# dm64lc_cslr_edmatc register map
Vendor: Texas Instruments
Peripheral module from a debugger description file.
Registers are 32-bit, access not given, reset 0x0 unless marked. A register's access mark holds for its fields unless they carry their own. Offsets are as the file gives them; lines under a group give offsets from that group; [hi:lo] are bit positions; {n}, {i} and the like mark numbered series; 'fields as' and 'values as' point back to an identical list; <NAME> marks a mode.

## EDMATC — Enhanced DMA Transfer controller.
0x00 REV ro reset 0x40003B00 — Peripheral Revision
  [31:0] PID — Reserved
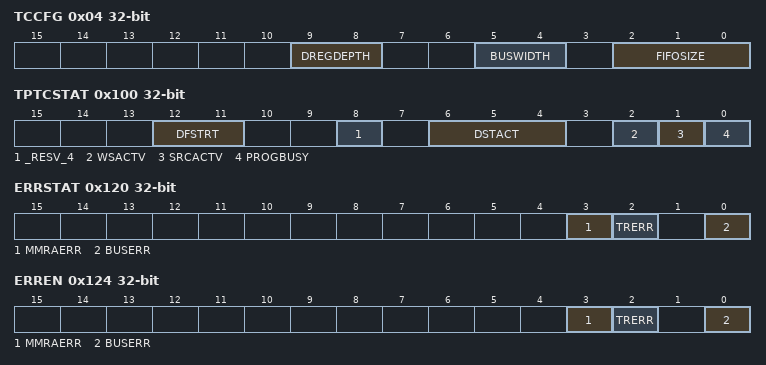
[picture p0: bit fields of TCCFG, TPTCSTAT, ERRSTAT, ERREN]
0x04 TCCFG — TC Configuration
  [9:8] DREGDEPTH ro — Dst Register FIFO Depth Parametization
    0=1ENTRY; 1=2ENTRY; 2=4ENTRY
  [5:4] BUSWIDTH ro
    0=32BIT; 1=64BIY (64-bit); 2=128BIT
  [2:0] FIFOSIZE ro
    0=32BYTE (32 Byte Fifo); 1=64BYTE (64 Byte Fifo); 2=128BYTE (128 Byte Fifo); 3=256BYTE (256 Byte Fifo); 4=512BYTE (512 Byte Fifo)
0x100 TPTCSTAT — TPTC Status
  [12:11] DFSTRT ro — Dst FIFO Start Pointer
  [8] _RESV_4 — Channel Active (access N)
    0=IDLE (Channel is Idle); 1=BUSY (Channel is busy)
  [6:4] DSTACT ro — Destination Active State
    0=EMPTY (Dst FIFO is empty); {v}={v}TR (Dst FIFO contains {v} TR) (v=1..4)
  [2] WSACTV ro — Write Status Active
    0=NONE (Write status is not pending); 1=PEND (Write Status is pending)
  [1] SRCACTV ro — Source Active State
    0=IDLE (Source Active set is idle and available for programming); 1=BUSY
  [0] PROGBUSY ro — Program Register Set Busy
    0=IDLE (Idle and available for programming); 1=BUSY
0x120 ERRSTAT — Error Status
  [3] MMRAERR ro — MMR Address Error Event
    0=NONE (No error detected); 1=ERROR (User attempted to read/write invalid address)
  [2] TRERR ro — TR Error Event
    0=NONE (Condition not detected); 1=ERROR (FIFO Mode transfer violation)
  [0] BUSERR ro — Bus Error Event
    0=NONE (Condition not detected); 1=ERROR (TC has detected an error code on the read response)
0x124 ERREN — Error Enable
  [all] fields
    1=ENABLE; 0=DISABLE
  [3] MMRAERR ro — MMR Address Error Event
  [2] TRERR ro — TR Error Event
  [0] BUSERR ro — Bus Error Event
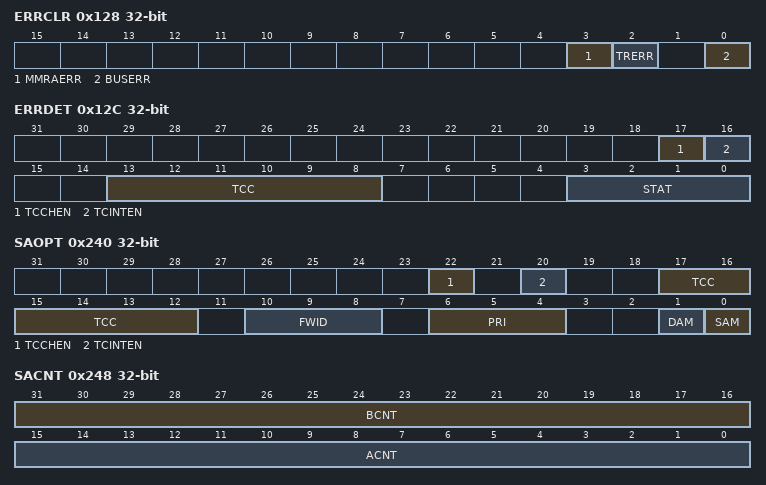
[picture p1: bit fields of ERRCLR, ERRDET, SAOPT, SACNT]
0x128 ERRCLR — Error Clear Register
  [all] fields
    1=CLEAR (Error Cleared)
  [3] MMRAERR ro — MMR Address Error Event
  [2] TRERR ro — TR Error Event
  [0] BUSERR ro — Bus Error Event
0x12C ERRDET — Error Details
  [17] TCCHEN ro — Transfer Completion Chaining Enable
  [16] TCINTEN ro — Transfer Completion Interrupt Enable
  [13:8] TCC ro — Transfer Completion Code
  [3:0] STAT ro — Transation Status
    0=NONE (No Error); 1=READ_ADDRESS (Read Addressing Error); 2=READ_PRIVILEGE (Read Privilege Error); 3=READ_TIMEOUT (Read Timeout Error); 4=READ_DATA (Read Data Error); 7=READ_EXCLUSIVE (Read Exclusive operation Error); 9=WRITE_ADDRESS (Write Addressing Error); 10=WRITE_PRIVILEGE (Write Privilege Error); 11=WRITE_TIMEOUT (Write Timeout Error); 12=WRITE_DATA (Write Data Error); 15=WRITE_EXCLUSIVE (Write Exclusive operation Error)
0x130 ERRCMD — Error Command
  [0] EVAL wo — Transfer Completion Interrupt Enable
    1=EVAL (Write of '1' causes tptc_errint to be pulsed if any of the ERRSTAT bits are set to '1')
0x140 RDRATE — Read Command rate
  [2:0] RDRATE rw — Read rate
    0=AFAP (As Fast as possible); 1=4CYCLE (4 cycles between reads); 2=8CYCLE (8 cycles between reads); 3=16CYCLE (16 cycles between reads); 4=32CYCLE (32 cycles between reads)
0x240 SAOPT — Src Actv Set Options
  [22] TCCHEN ro — Transfer Complete chaining enable
    0=DISABLE (Transfer complete chaning disable); 1=ENABLE (Transfer complete chaning enable)
  [20] TCINTEN ro — Transfer Complete interrupt enable
    0=DISABLE (Transfer complete interrupt disable); 1=ENABLE (Transfer complete interrupt enable)
  [17:12] TCC ro — Transfer Complete Code
  [10:8] FWID ro — Fifo Width
    0=8BIT (Fifo Width is 8-bit); 1=16BIT (Fifo Width is 16-bit); 2=32BIT (Fifo Width is 32-bit); 3=64BIT (Fifo Width is 64-bit); 4=128BIT (Fifo Width is 128-bit); 5=256BIT (Fifo Width is 256-bit)
  [6:4] PRI ro — Transfer Priority
  [1] DAM ro — Destination address mode within array
    0=INCR (Dst addressing within array increments); 1=FIFO (Dst addressing within array wraps around upon reaching FIFO width)
  [0] SAM ro — Source address mode within array
    0=INCR (Src addressing within array increments); 1=FIFO (Src addressing within array wraps around upon reaching FIFO width)
0x244 SASRC ro — Src Actv Set Src Address
  [31:0] SADDR — Source address for Program Register Set
0x248 SACNT ro — Src Actv Set Count
  [31:16] BCNT — B Dimension count
  [15:0] ACNT — A Dimension count
0x24C SADST — Src Actv Dst address
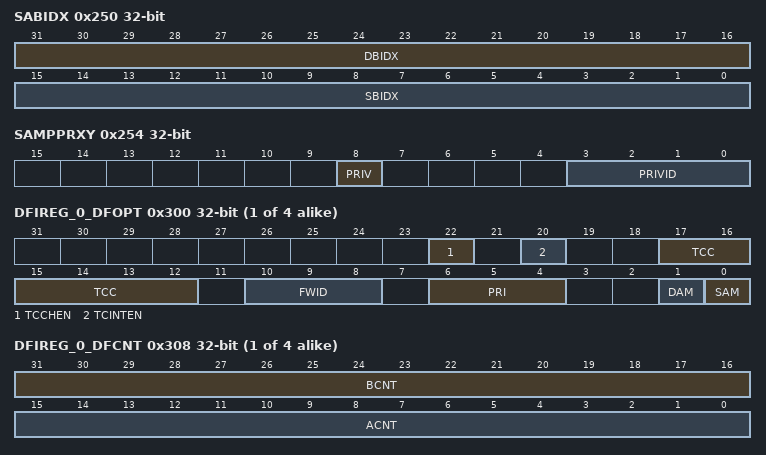
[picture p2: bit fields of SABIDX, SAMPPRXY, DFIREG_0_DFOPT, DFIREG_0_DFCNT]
0x250 SABIDX rw — Src Actv Set B-Dim Idx
  [31:16] DBIDX — B-Idx offset between Destination arrays
  [15:0] SBIDX — B-Idx offset between Source arrays
0x254 SAMPPRXY — Src Actv Set Mem Protect Proxy
  [8] PRIV ro — Privilege Level
    0=USER (User level privilege); 1=SUPERVISOR (Supervisor level privilege)
  [3:0] PRIVID ro — Privilege ID
0x258 SACNTRLD — Src Actv Set Cnt Reload
  [15:0] ACNTRLD ro — A-cnt Reload value
0x25C SASRCBREF ro — Src Actv Set Src Address B-reference
  [31:0] SADDRBREFG — Source address B-Reference
0x260 SADSTBREF — Src Actv Set Dst Address B-reference
0x280 DFCNTRLD — Dst FIFO Set Cnt Reload
  [15:0] ACNTRLD ro — A-Cnt Reload value
0x284 DFSRCBREF — Dst FIFO Set Dst Addr B Reference
0x288 DFDSTBREF ro — Dst FIFO Set Dst Addr B Reference
  [31:0] DADDRBREF — Destination address reference for Dst FIFO Register Set
{0x300+0x40*i} DFIREG_{i}_DFOPT (i=0..3) — Dst FIFO Set Option
  [22] TCCHEN ro — Transfer Complete chaining enable
    values as SAOPT.TCCHEN
  [20] TCINTEN ro — Transfer Complete interrupt enable
    values as SAOPT.TCINTEN
  [17:12] TCC ro — Transfer Complete Code
  [10:8] FWID ro — Fifo Width
    values as SAOPT.FWID
  [6:4] PRI ro — Transfer Priority
  [1] DAM ro — Destination address mode within array
    0=INCR (Dst addressing within array increments); 1=CONST (Dst addressing within array wraps around upon reaching FIFO width)
  [0] SAM ro — Source address mode within array
    0=INCR (Src addressing within array increments); 1=CONST (Src addressing within array wraps around upon reaching FIFO width)
{0x304+0x40*i} DFIREG_{i}_DFSRC (i=0..3) — Dst Fifo Source address
{0x308+0x40*i} DFIREG_{i}_DFCNT ro (i=0..3) — Dst Fifo Set Count
  [31:16] BCNT — B Dimension count
  [15:0] ACNT — A Dimension count
{0x30C+0x40*i} DFIREG_{i}_DFDST ro (i=0..3) — Dst Fifo Set Dst Count
  [31:0] DADDR — Dst Address
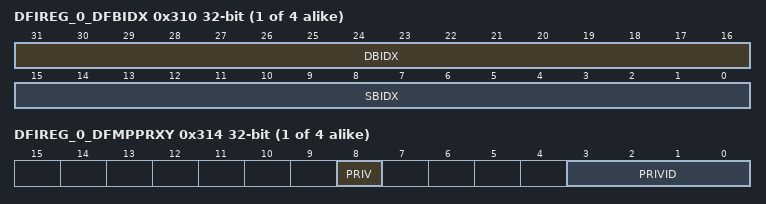
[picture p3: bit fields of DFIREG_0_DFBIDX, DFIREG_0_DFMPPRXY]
{0x310+0x40*i} DFIREG_{i}_DFBIDX ro (i=0..3) — Dst Fifo Set B-Dim Idx
  fields as SABIDX
{0x314+0x40*i} DFIREG_{i}_DFMPPRXY (i=0..3) — Dst Fifo mem Protect Proxy
  fields as SAMPPRXY
